# DMASS_PSILSS_0_DMASS_PSILSS_0_PSILSS_MMRS_48140000h register map
Vendor: Texas Instruments
Peripheral module from a debugger description file (folder am62L).
Registers are 32-bit, read-only, reset 0x0 unless marked. A register's access mark holds for its fields unless they carry their own. Offsets are as the file gives them; lines under a group give offsets from that group; [hi:lo] are bit positions; {n}, {i} and the like mark numbered series; 'fields as' and 'values as' point back to an identical list; <NAME> marks a mode.

## DMASS_PSILSS_0_PSILSS_MMRS
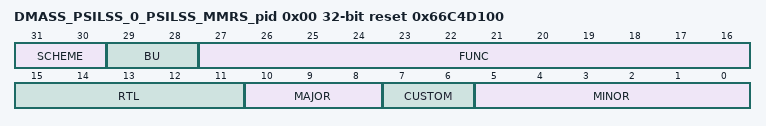
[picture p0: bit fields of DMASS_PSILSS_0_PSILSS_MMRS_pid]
0x00 DMASS_PSILSS_0_PSILSS_MMRS_pid reset 0x66C4D100 — The Revision Register contains the major and minor revisions for the module.
  [31:30] SCHEME — PID register scheme Reset Source: rst_mod_g_rst_n
  [29:28] BU — Business Unit: 10 = Processors Reset Source: rst_mod_g_rst_n
  [27:16] FUNC — Module ID Reset Source: rst_mod_g_rst_n
  [15:11] RTL — RTL revision. Will vary depending on release. Reset Source: rst_mod_g_rst_n
  [10:8] MAJOR — Major revision Reset Source: rst_mod_g_rst_n
  [7:6] CUSTOM — Custom Reset Source: rst_mod_g_rst_n
  [5:0] MINOR — Minor revision Reset Source: rst_mod_g_rst_n
0x04 DMASS_PSILSS_0_PSILSS_MMRS_config reset 0xA — The Config Register shows configured params.
  [15:0] ENDPOINTS — Number of endpoints supported. Reset Source: rst_mod_g_rst_n
0x10 DMASS_PSILSS_0_PSILSS_MMRS_event rw reset 0xFFFF — The Event Register defines the event to produce for a link down event.
  [15:0] EVT — The event to produce. Reset Source: rst_mod_g_rst_n
0x20 DMASS_PSILSS_0_PSILSS_MMRS_link — The Link Register shows the current status of the endpoint links.
  [31:0] STATUS — The status of the endpoint links. Indices:0: .pdma_spi_psil 1: .pdma_uart_psil 2: .pdma_mcasp_psil 3: .pdma_crypto_psil 4: .cpsw2_psil 5: pktdma.strm 6: pktdma.cfgstrm 7: bcdma.cfgstrm 8: bcdma.strm 9: psilcfg.cfgstrm Reset Source: rst_mod_g_rst_n
0x40 DMASS_PSILSS_0_PSILSS_MMRS_down access not given — The Link Down Register shows which links are down for the endpoints.
  [31:0] STATUS — The down status of the endpoint links. Indices:0: .pdma_spi_psil 1: .pdma_uart_psil 2: .pdma_mcasp_psil 3: .pdma_crypto_psil 4: .cpsw2_psil 5: pktdma.strm 6: pktdma.cfgstrm 7: bcdma.cfgstrm 8: bcdma.strm 9: psilcfg.cfgstrm Reset Source: rst_mod_g_rst_n (access R/W1TC)
